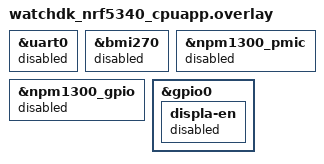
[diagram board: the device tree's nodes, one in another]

&uart0 {
    status = "disabled";
};

&bmi270 {
    status = "disabled";
};

&npm1300_pmic {
    status = "disabled";
};

&npm1300_gpio {
    status = "disabled";
};

&gpio0 {
    displa-en {
        status = "disabled";
    };
};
